# RE01_1500KB register map
Vendor: Renesas Electronics Corporation; Series: RE01_1500KB; File version: 1.20
CPU: CM0PLUS r0p1, little endian, MPU, no FPU, VTOR, 2 interrupt priority bits
Registers are 8-bit, read-write, reset 0x0 unless marked. A register's access mark holds for its fields unless they carry their own. Offsets are from the block's base; [hi:lo] are bit positions; {n}, {i} and the like mark numbered series.

## OSM — Option Setting Memory
Base 0x00000400; alternate view of FLASH
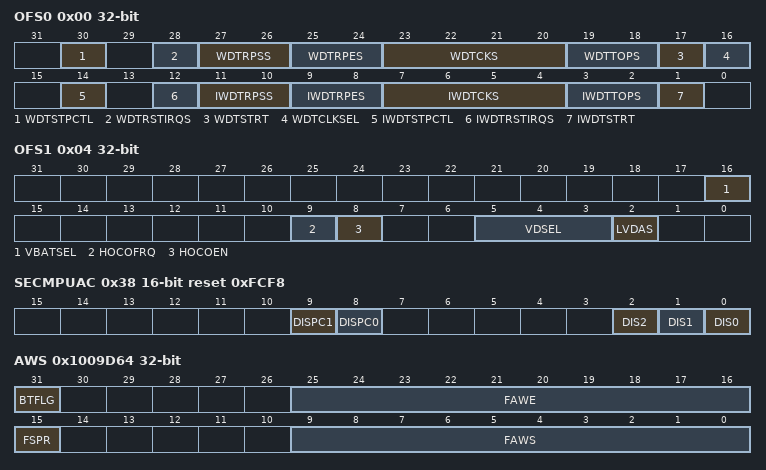
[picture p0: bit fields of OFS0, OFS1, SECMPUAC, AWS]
0x00 OFS0 32-bit ro reset not defined — Option Function Select Register 0
  [30] WDTSTPCTL — WDT Stop Control
  [28] WDTRSTIRQS — WDT Reset Interrupt Request Select
    0=NMI; 1=Reset
  [27:26] WDTRPSS — WDT Window Start Position Select
    0=25 percent; 1=50 percent; 2=75 percent; 3=100 percent (No window start position setting)
  [25:24] WDTRPES — WDT Window End Position Select
    0=75 percent; 1=50 percent; 2=25 percent; 3=0 percent (No window end position setting)
  [23:20] WDTCKS — WDT Clock Frequency Division Ratio Select
    1=WDTCLK divided by 4; 4=WDTCLK divided by 64; 15=WDTCLK divided by 128; 6=WDTCLK divided by 512; 7=WDTCLK divided by 2048; 8=WDTCLK divided by 8192; other=others (Settings are prohibited)
  [19:18] WDTTOPS — WDT Timeout Period Select
    0=1024 cycles (03FFh); 1=4096 cycles (0FFFh); 2=8192 cycles (1FFFh); 3=16384 cycles (3FFFh)
  [17] WDTSTRT — WDT Start Mode Select
    0=Automatically activate WDT after a reset (auto-start mode); 1=Stop WDT after a reset (register-start mode)
  [16] WDTCLKSEL
  [14] IWDTSTPCTL — IWDT Stop Control
    0=Continue counting; 1=Stop counting when in Sleep mode, Snooze mode, or Software Standby mode
  [12] IWDTRSTIRQS — IWDT Reset Interrupt Request Select
    0=Enable non-maskable interrupt request or interrupt request; 1=Enable reset
  [11:10] IWDTRPSS — IWDT Window Start Position Select
    0=25 percent; 1=50 percent; 2=75 percent; 3=100 percent (no window start position setting)
  [9:8] IWDTRPES — IWDT Window End Position Select
    0=75 percent; 1=50 percent; 2=25 percent; 3=0 percent (no window end position setting)
  [7:4] IWDTCKS — IWDT-Dedicated Clock Frequency Division Ratio Select
    0=x 1; 2=x 1/16; 3=x 1/32; 4=x 1/64; 15=x 1/128; 5=x 1/256; other=others (settings are prohibited.)
  [3:2] IWDTTOPS — IWDT Timeout Period Select
    0=128 cycles (007Fh); 1=512 cycles (01FFh); 2=1024 cycles (03FFh); 3=2048 cycles (07FFh)
  [1] IWDTSTRT — IWDT Start Mode Select
    0=Automatically activate IWDT after a reset (auto-start mode); 1=Disable IWDT
0x04 OFS1 32-bit ro reset not defined — Option Function Select Register 1
  [16] VBATSEL
  [9] HOCOFRQ — HOCO Frequency Setting
    0=24 MHz; 1=32 MHz
  [8] HOCOEN — HOCO Oscillation Enable
    0=Enable HOCO oscillation after a reset; 1=Disable HOCO oscillation after a reset
  [5:3] VDSEL — Voltage Detection 0 Level Select
    0=000; 1=001; 2=010; 3=011
  [2] LVDAS — Voltage Detection 0 Circuit Start
    0=Enable voltage monitor 0 reset after a reset; 1=Disable voltage monitor 0 reset after a reset
0x08 SECMPUPCS0 32-bit ro reset not defined — Security MPU Program Counter Start Address Register 0
0x0C SECMPUPCE0 32-bit ro reset not defined — Security MPU Program Counter End Address Register 0
0x10 SECMPUPCS1 32-bit ro reset not defined — Security MPU Program Counter Start Address Register 1
0x14 SECMPUPCE1 32-bit ro reset not defined — Security MPU Program Counter End Address Register 1
{0x18+8i} SECMPUS{i} 32-bit ro reset not defined (i=0..2) — Security MPU Region {i} Start Address Register
{0x1C+8i} SECMPUE{i} 32-bit ro reset not defined (i=0..2) — Security MPU Region {i} End Address Register
0x38 SECMPUAC 16-bit ro reset 0xFCF8 (reset mask 0xFCF8) — Security MPU Access Control Register
  [9] DISPC1 — PC Region 1 Disable
    0=Security MPU PC Region 1 is enabled; 1=Security MPU PC Region 1 is disabled
  [8] DISPC0 — PC Region 0 Disable
    0=Security MPU PC Region 0 is enabled; 1=Security MPU PC Region 0 is disabled
  [2] DIS2 — Region 2 Disable
    0=Security MPU Region 2 is enabled; 1=Security MPU Region 2 is disabled
  [1] DIS1 — Region 1 Disable
    0=Security MPU Region 1 is enabled; 1=Security MPU Region 1 is disabled
  [0] DIS0 — Region 0 Disable
    0=Security MPU Region 0 is enabled; 1=Security MPU Region 0 is disabled
{0x1009D50+4i} OSIS[{i}] (i=0..3) 32-bit ro reset not defined — OCD/Serial Programmer ID Setting Register
  [31:0] OSIS — These fields hold the ID for use in ID authentication for the OCD/serial programmer.
0x1009D64 AWS 32-bit ro reset not defined — Access Window Setting Register
  [31] BTFLG
  [25:16] FAWE — Access Window End Block AddressThese bits specify the end block address for the access window.They do not represent the block number of the access window.The access window is only valid in the program flash area. The end block address for the access window is the next block to the P/E acceptable region defined by the access window.The block address specifies the first address of the block and consists of the address bits [21:10].
  [15] FSPR
  [9:0] FAWS — Access Window Start Block AddressThese bits specify the start block address for the access window.They do not represent the block number of the access window.The access window is only valid in the program flash area. The block address specifies the first address of the block and consists of the address bits [21:10].
